VERSION "created by canmatrix"

NS_ :

BS_:

BU_: User ADM_PC_LL25 ADM_PC_BC25 ADM_PC_BP25 ADM_PC_BI25

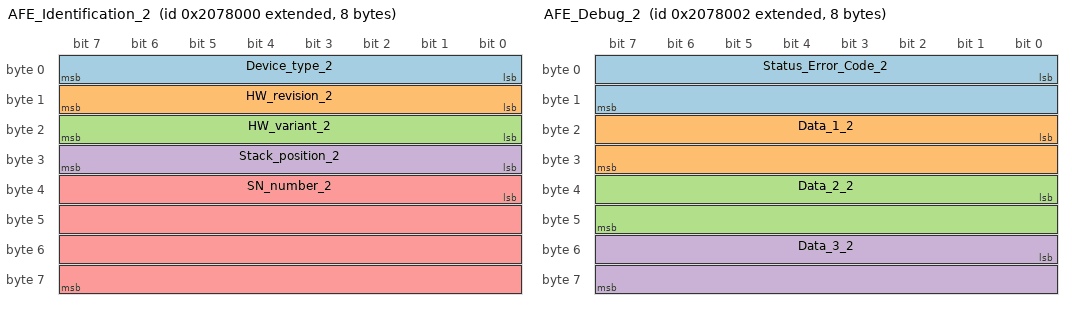
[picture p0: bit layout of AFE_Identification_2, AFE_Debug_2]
BO_ 2181529600 AFE_Identification_2: 8 ADM_PC_BP25
 SG_ Device_type_2 : 0|8@1+ (1,0) [0|255] "" Vector__XXX
 SG_ HW_revision_2 : 8|8@1+ (1,0) [0|255] "" Vector__XXX
 SG_ HW_variant_2 : 16|8@1+ (1,0) [0|255] "" Vector__XXX
 SG_ Stack_position_2 : 24|8@1+ (1,0) [0|255] "" Vector__XXX
 SG_ SN_number_2 : 32|32@1+ (1,0) [0|4294967295] "" Vector__XXX

BO_ 2181529601 AFE_FwInfo_2: 8 ADM_PC_BP25
 SG_ FW_info_mux_2 M : 56|8@1+ (1,0) [0|255] "" Vector__XXX
 SG_ FW_revision_0_2 m0 : 0|8@1+ (1,0) [0|255] "" Vector__XXX
 SG_ FW_revision_1_2 m0 : 8|8@1+ (1,0) [0|255] "" Vector__XXX
 SG_ FW_revision_2_2 m0 : 16|8@1+ (1,0) [0|255] "" Vector__XXX
 SG_ FW_revision_3_2 m0 : 24|8@1+ (1,0) [0|255] "" Vector__XXX
 SG_ FW_revision_4_2 m0 : 32|8@1+ (1,0) [0|255] "" Vector__XXX
 SG_ FW_revision_5_2 m0 : 40|8@1+ (1,0) [0|255] "" Vector__XXX
 SG_ FW_revision_6_2 m0 : 48|8@1+ (1,0) [0|255] "" Vector__XXX
 SG_ FW_revision_7_2 m1 : 0|8@1+ (1,0) [0|255] "" Vector__XXX
 SG_ FW_revision_8_2 m1 : 8|8@1+ (1,0) [0|255] "" Vector__XXX
 SG_ FW_revision_9_2 m1 : 16|8@1+ (1,0) [0|255] "" Vector__XXX
 SG_ FW_revision_10_2 m1 : 24|8@1+ (1,0) [0|255] "" Vector__XXX
 SG_ FW_revision_11_2 m1 : 32|8@1+ (1,0) [0|255] "" Vector__XXX
 SG_ FW_revision_12_2 m1 : 40|8@1+ (1,0) [0|255] "" Vector__XXX
 SG_ FW_revision_13_2 m1 : 48|8@1+ (1,0) [0|255] "" Vector__XXX
 SG_ FW_datecode_0_2 m2 : 0|8@1+ (1,0) [0|255] "" Vector__XXX
 SG_ FW_datecode_1_2 m2 : 8|8@1+ (1,0) [0|255] "" Vector__XXX
 SG_ FW_datecode_2_2 m2 : 16|8@1+ (1,0) [0|255] "" Vector__XXX
 SG_ FW_datecode_3_2 m2 : 24|8@1+ (1,0) [0|255] "" Vector__XXX
 SG_ FW_datecode_4_2 m2 : 32|8@1+ (1,0) [0|255] "" Vector__XXX
 SG_ FW_datecode_5_2 m2 : 40|8@1+ (1,0) [0|255] "" Vector__XXX
 SG_ FW_datecode_6_2 m2 : 48|8@1+ (1,0) [0|255] "" Vector__XXX
 SG_ FW_datecode_7_2 m3 : 0|8@1+ (1,0) [0|255] "" Vector__XXX
 SG_ FW_datecode_8_2 m3 : 8|8@1+ (1,0) [0|255] "" Vector__XXX
 SG_ FW_datecode_9_2 m3 : 16|8@1+ (1,0) [0|255] "" Vector__XXX
 SG_ FW_datecode_10_2 m3 : 24|8@1+ (1,0) [0|255] "" Vector__XXX
 SG_ FW_datecode_11_2 m3 : 32|8@1+ (1,0) [0|255] "" Vector__XXX
 SG_ FW_datecode_12_2 m3 : 40|8@1+ (1,0) [0|255] "" Vector__XXX
 SG_ FW_datecode_13_2 m3 : 48|8@1+ (1,0) [0|255] "" Vector__XXX

BO_ 2181529613 _AFE_Boot_FwInfo_2: 8 ADM_PC_BP25
 SG_ Boot_FW_info_mux_2 M : 56|8@1+ (1,0) [0|255] "" Vector__XXX
 SG_ FW_revision_0_2 m0 : 0|8@1+ (1,0) [0|255] "" Vector__XXX
 SG_ FW_revision_1_2 m0 : 8|8@1+ (1,0) [0|255] "" Vector__XXX
 SG_ FW_revision_2_2 m0 : 16|8@1+ (1,0) [0|255] "" Vector__XXX
 SG_ FW_revision_3_2 m0 : 24|8@1+ (1,0) [0|255] "" Vector__XXX
 SG_ FW_revision_4_2 m0 : 32|8@1+ (1,0) [0|255] "" Vector__XXX
 SG_ FW_revision_5_2 m0 : 40|8@1+ (1,0) [0|255] "" Vector__XXX
 SG_ FW_revision_6_2 m0 : 48|8@1+ (1,0) [0|255] "" Vector__XXX
 SG_ FW_revision_7_2 m1 : 0|8@1+ (1,0) [0|255] "" Vector__XXX
 SG_ FW_revision_8_2 m1 : 8|8@1+ (1,0) [0|255] "" Vector__XXX
 SG_ FW_revision_9_2 m1 : 16|8@1+ (1,0) [0|255] "" Vector__XXX
 SG_ FW_revision_10_2 m1 : 24|8@1+ (1,0) [0|255] "" Vector__XXX
 SG_ FW_revision_11_2 m1 : 32|8@1+ (1,0) [0|255] "" Vector__XXX
 SG_ FW_revision_12_2 m1 : 40|8@1+ (1,0) [0|255] "" Vector__XXX
 SG_ FW_revision_13_2 m1 : 48|8@1+ (1,0) [0|255] "" Vector__XXX
 SG_ FW_datecode_0_2 m2 : 0|8@1+ (1,0) [0|255] "" Vector__XXX
 SG_ FW_datecode_1_2 m2 : 8|8@1+ (1,0) [0|255] "" Vector__XXX
 SG_ FW_datecode_2_2 m2 : 16|8@1+ (1,0) [0|255] "" Vector__XXX
 SG_ FW_datecode_3_2 m2 : 24|8@1+ (1,0) [0|255] "" Vector__XXX
 SG_ FW_datecode_4_2 m2 : 32|8@1+ (1,0) [0|255] "" Vector__XXX
 SG_ FW_datecode_5_2 m2 : 40|8@1+ (1,0) [0|255] "" Vector__XXX
 SG_ FW_datecode_6_2 m2 : 48|8@1+ (1,0) [0|255] "" Vector__XXX
 SG_ FW_datecode_7_2 m3 : 0|8@1+ (1,0) [0|255] "" Vector__XXX
 SG_ FW_datecode_8_2 m3 : 8|8@1+ (1,0) [0|255] "" Vector__XXX
 SG_ FW_datecode_9_2 m3 : 16|8@1+ (1,0) [0|255] "" Vector__XXX
 SG_ FW_datecode_10_2 m3 : 24|8@1+ (1,0) [0|255] "" Vector__XXX
 SG_ FW_datecode_11_2 m3 : 32|8@1+ (1,0) [0|255] "" Vector__XXX
 SG_ FW_datecode_12_2 m3 : 40|8@1+ (1,0) [0|255] "" Vector__XXX
 SG_ FW_datecode_13_2 m3 : 48|8@1+ (1,0) [0|255] "" Vector__XXX

BO_ 2181529602 AFE_Debug_2: 8 ADM_PC_BP25
 SG_ Status_Error_Code_2 : 0|16@1+ (1,0) [0|65535] "" Vector__XXX
 SG_ Data_1_2 : 16|16@1+ (1,0) [0|65535] "" Vector__XXX
 SG_ Data_2_2 : 32|16@1+ (1,0) [0|65535] "" Vector__XXX
 SG_ Data_3_2 : 48|16@1+ (1,0) [0|65535] "" Vector__XXX

BO_ 2181529607 AFE_Status_2: 8 ADM_PC_BP25
 SG_ Running_2 : 0|1@1+ (1,0) [0|1] "" Vector__XXX
 SG_ PWM_2 : 1|1@1+ (1,0) [0|1] "" Vector__XXX
 SG_ Current_dc_loop_mode_2 : 2|1@1+ (1,0) [0|1] "" Vector__XXX
 SG_ Current_ac_loop_mode_2 : 3|1@1+ (1,0) [0|1] "" Vector__XXX
 SG_ Buck_2 : 5|1@1+ (1,0) [0|1] "" Vector__XXX
 SG_ Boost_2 : 6|1@1+ (1,0) [0|1] "" Vector__XXX
 SG_ Precharge_dc_buck_mode_2 : 7|1@1+ (1,0) [0|1] "" Vector__XXX
 SG_ Precharge_dc_boost_mode_2 : 8|1@1+ (1,0) [0|1] "" Vector__XXX
 SG_ Rectifier_3ph_2 : 9|1@1+ (1,0) [0|1] "" Vector__XXX
 SG_ Stack_mode_2 : 10|1@1+ (1,0) [0|1] "" Vector__XXX
 SG_ Master_2 : 11|1@1+ (1,0) [0|1] "" Vector__XXX
 SG_ Slave_2 : 12|1@1+ (1,0) [0|1] "" Vector__XXX
 SG_ Inverter_1ph_2 : 13|1@1+ (1,0) [0|1] "" Vector__XXX
 SG_ Boost_Neutral_2 : 14|1@1+ (1,0) [0|1] "" Vector__XXX
 SG_ Rectifier_1ph_2 : 15|1@1+ (1,0) [0|1] "" Vector__XXX
 SG_ Inverter_3ph_2 : 16|1@1+ (1,0) [0|1] "" Vector__XXX
 SG_ Ready_2 : 17|1@1+ (1,0) [0|1] "" Vector__XXX
 SG_ Inverter_1ph_Sync_2 : 18|1@1+ (1,0) [0|1] "" Vector__XXX
 SG_ Neutral_2 : 19|1@1+ (1,0) [0|1] "" Vector__XXX
 SG_ Rectifier_1ph_Buck_2 : 20|1@1+ (1,0) [0|1] "" Vector__XXX
 SG_ Inverter_1ph_Boost_2 : 21|1@1+ (1,0) [0|1] "" Vector__XXX
 SG_ Rectifier_distributed_2 : 22|1@1+ (1,0) [0|1] "" Vector__XXX
 SG_ MPPT_buck_2 : 23|1@1+ (1,0) [0|1] "" Vector__XXX
 SG_ MPPT_boost_2 : 24|1@1+ (1,0) [0|1] "" Vector__XXX
 SG_ Buck_2p_float_2 : 25|1@1+ (1,0) [0|1] "" Vector__XXX
 SG_ Inverter_1ph_Distributed_2 : 26|1@1+ (1,0) [0|1] "" Vector__XXX

BO_ 2181529606 AFE_Faults_2: 3 ADM_PC_BP25
 SG_ Protection_trip_internal_2 : 0|1@1+ (1,0) [0|1] "" Vector__XXX
 SG_ Protection_trip_external_2 : 1|1@1+ (1,0) [0|1] "" Vector__XXX
 SG_ Phase_U_overcurrent_2 : 2|1@1+ (1,0) [0|1] "" Vector__XXX
 SG_ Phase_U_overvoltage_2 : 3|1@1+ (1,0) [0|1] "" Vector__XXX
 SG_ Phase_U_undervoltage_2 : 4|1@1+ (1,0) [0|1] "" Vector__XXX
 SG_ Phase_V_overvoltage_2 : 5|1@1+ (1,0) [0|1] "" Vector__XXX
 SG_ Phase_V_undervoltage_2 : 6|1@1+ (1,0) [0|1] "" Vector__XXX
 SG_ Phase_V_overcurrent_2 : 7|1@1+ (1,0) [0|1] "" Vector__XXX
 SG_ Phase_W_overvoltage_2 : 8|1@1+ (1,0) [0|1] "" Vector__XXX
 SG_ Phase_W_undervoltage_2 : 9|1@1+ (1,0) [0|1] "" Vector__XXX
 SG_ Phase_W_overcurrent_2 : 10|1@1+ (1,0) [0|1] "" Vector__XXX
 SG_ DC_undervoltage_2 : 11|1@1+ (1,0) [0|1] "" Vector__XXX
 SG_ DC_overvoltage_2 : 12|1@1+ (1,0) [0|1] "" Vector__XXX
 SG_ MOSFET_overtemperature_2 : 13|1@1+ (1,0) [0|1] "" Vector__XXX
 SG_ Inductor_overtemperature_2 : 14|1@1+ (1,0) [0|1] "" Vector__XXX
 SG_ Keep_Alive_not_served_2 : 15|1@1+ (1,0) [0|1] "" Vector__XXX
 SG_ PLL_not_locked_2 : 16|1@1+ (1,0) [0|1] "" Vector__XXX
 SG_ NFO_2 : 20|1@1+ (1,0) [0|1] "" Vector__XXX
 SG_ Measurement_system_failure_2 : 21|1@1+ (1,0) [0|1] "" Vector__XXX
 SG_ EEPROM_failure_2 : 22|1@1+ (1,0) [0|1] "" Vector__XXX
 SG_ System_2 : 23|1@1+ (1,0) [0|1] "" Vector__XXX

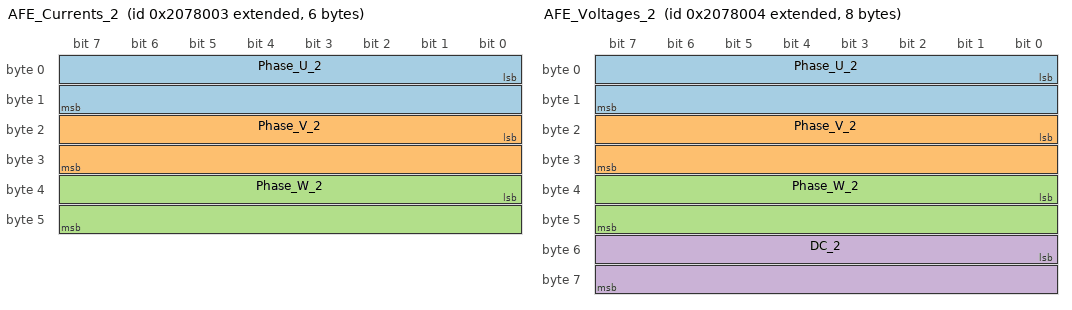
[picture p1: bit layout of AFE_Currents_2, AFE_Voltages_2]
BO_ 2181529603 AFE_Currents_2: 6 ADM_PC_BP25
 SG_ Phase_U_2 : 0|16@1- (0.01,0) [-327.68|327.67] "A" Vector__XXX
 SG_ Phase_V_2 : 16|16@1- (0.01,0) [-327.68|327.67] "A" Vector__XXX
 SG_ Phase_W_2 : 32|16@1- (0.01,0) [-327.68|327.67] "A" Vector__XXX

BO_ 2181529616 AFE_DC_Bus_current_2: 2 ADM_PC_BP25
 SG_ Bus_current_2 : 0|16@1- (0.01,0) [-327.68|327.67] "A" Vector__XXX

BO_ 2181529614 _AFE_Broadcast_2: 8 ADM_PC_BP25
 SG_ Diagnostics_Index_2 M : 56|8@1+ (1,0) [0|255] "" Vector__XXX
 SG_ Phase_U_2 m1 : 8|16@1- (0.01,0) [-327.68|327.67] "A" ADM_PC_BP25
 SG_ Phase_V_2 m1 : 24|16@1- (0.01,0) [-327.68|327.67] "A" ADM_PC_BP25
 SG_ Phase_W_2 m1 : 40|16@1- (0.01,0) [-327.68|327.67] "A" ADM_PC_BP25
 SG_ Stack_position_2 : 0|5@1+ (1,0) [0|31] "" ADM_PC_BP25
 SG_ Group_ID_2 : 5|3@1+ (1,0) [0|7] "" ADM_PC_BP25

BO_ 2181529604 AFE_Voltages_2: 8 ADM_PC_BP25
 SG_ Phase_U_2 : 0|16@1- (0.1,0) [-3276.8|3276.7] "V" Vector__XXX
 SG_ Phase_V_2 : 16|16@1- (0.1,0) [-3276.8|3276.7] "V" Vector__XXX
 SG_ Phase_W_2 : 32|16@1- (0.1,0) [-3276.8|3276.7] "V" Vector__XXX
 SG_ DC_2 : 48|16@1- (0.1,0) [-3276.8|3276.7] "V" Vector__XXX

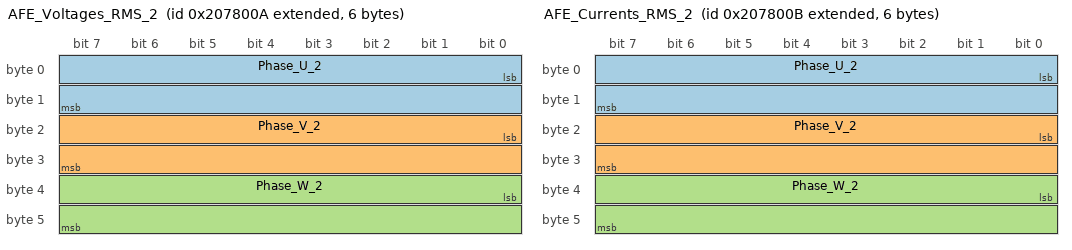
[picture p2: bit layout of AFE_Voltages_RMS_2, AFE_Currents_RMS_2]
BO_ 2181529610 AFE_Voltages_RMS_2: 6 ADM_PC_BP25
 SG_ Phase_U_2 : 0|16@1+ (0.1,0) [0|6553.5] "V" Vector__XXX
 SG_ Phase_V_2 : 16|16@1+ (0.1,0) [0|6553.5] "V" Vector__XXX
 SG_ Phase_W_2 : 32|16@1+ (0.1,0) [0|6553.5] "V" Vector__XXX

BO_ 2181529611 AFE_Currents_RMS_2: 6 ADM_PC_BP25
 SG_ Phase_U_2 : 0|16@1+ (0.01,0) [0.00|655.35] "A" Vector__XXX
 SG_ Phase_V_2 : 16|16@1+ (0.01,0) [0.00|655.35] "A" Vector__XXX
 SG_ Phase_W_2 : 32|16@1+ (0.01,0) [0.00|655.35] "A" Vector__XXX

BO_ 2181529612 AFE_Mains_2: 4 ADM_PC_BP25
 SG_ Frequency_2 : 0|16@1+ (0.01,0) [0.00|655.35] "Hz" Vector__XXX
 SG_ Phase_2 : 16|16@1- (0.1,0) [-3276.8|3276.7] "Deg." Vector__XXX

BO_ 2181529605 AFE_Temperatures_2: 4 ADM_PC_BP25
 SG_ Temp_Bridge_2 : 0|16@1- (0.01,0) [-327.68|327.67] "°C" Vector__XXX
 SG_ Temp_Inductors_2 : 16|16@1- (0.01,0) [-327.68|327.67] "°C" Vector__XXX

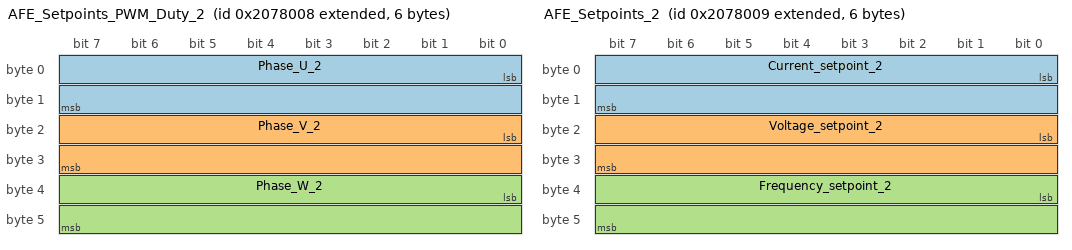
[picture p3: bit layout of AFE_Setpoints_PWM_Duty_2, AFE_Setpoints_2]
BO_ 2181529608 AFE_Setpoints_PWM_Duty_2: 6 ADM_PC_BP25
 SG_ Phase_U_2 : 0|16@1+ (0.001525902,0) [0E-009|99.999987570] "%" Vector__XXX
 SG_ Phase_V_2 : 16|16@1+ (0.001525902,0) [0E-009|99.999987570] "%" Vector__XXX
 SG_ Phase_W_2 : 32|16@1+ (0.001525902,0) [0E-009|99.999987570] "%" Vector__XXX

BO_ 2181529609 AFE_Setpoints_2: 6 ADM_PC_BP25
 SG_ Current_setpoint_2 : 0|16@1- (0.01,0) [-327.68|327.67] "A" Vector__XXX
 SG_ Voltage_setpoint_2 : 16|16@1+ (0.1,0) [0|6553.5] "V" Vector__XXX
 SG_ Frequency_setpoint_2 : 32|16@1+ (0.01,0) [0.00|655.35] "Hz" Vector__XXX

BO_ 2181496928 AFE_Keep_Alive_2: 1 User
 SG_ Keep_Alive_Enable_2 : 0|1@1+ (1,0) [0|1] "" ADM_PC_BP25

BO_ 2181496896 AFE_Mode_Control_2: 8 User
 SG_ Converter_ON_2 : 0|1@1+ (1,0) [0|1] "" ADM_PC_BP25
 SG_ PWM_ON_2 : 1|1@1+ (1,0) [0|1] "" ADM_PC_BP25
 SG_ DC_Current_feedback_ON_2 : 2|1@1+ (1,0) [0|1] "" ADM_PC_BP25
 SG_ AC_Current_feedback_ON_2 : 3|1@1+ (1,0) [0|1] "" ADM_PC_BP25
 SG_ Buck_ON_2 : 5|1@1+ (1,0) [0|1] "" ADM_PC_BP25
 SG_ Boost_ON_2 : 6|1@1+ (1,0) [0|1] "" ADM_PC_BP25
 SG_ Rectifier_3ph_ON_2 : 9|1@1+ (1,0) [0|1] "" ADM_PC_BP25
 SG_ Inverter_1ph_ON_2 : 10|1@1+ (1,0) [0|1] "" ADM_PC_BP25
 SG_ Rectifier_1ph_ON_2 : 11|1@1+ (1,0) [0|1] "" ADM_PC_BP25
 SG_ Boost_Neutral_ON_2 : 12|1@1+ (1,0) [0|1] "" ADM_PC_BP25
 SG_ Inverter_3ph_ON_2 : 13|1@1+ (1,0) [0|1] "" ADM_PC_BP25
 SG_ Inverter_1ph_Sync_ON_2 : 14|1@1+ (1,0) [0|1] "" ADM_PC_BP25
 SG_ Neutral_ON_2 : 15|1@1+ (1,0) [0|1] "" ADM_PC_BP25
 SG_ Rectifier_1ph_Buck_ON_2 : 16|1@1+ (1,0) [0|1] "" ADM_PC_BP25
 SG_ Inverter_1ph_Boost_ON_2 : 17|1@1+ (1,0) [0|1] "" ADM_PC_BP25
 SG_ Rectifier_Distributed_ON_2 : 18|1@1+ (1,0) [0|1] "" ADM_PC_BP25
 SG_ MPPT_buck_ON_2 : 19|1@1+ (1,0) [0|1] "" ADM_PC_BP25
 SG_ MPPT_boost_ON_2 : 20|1@1+ (1,0) [0|1] "" ADM_PC_BP25
 SG_ Buck_2p_float_ON_2 : 21|1@1+ (1,0) [0|1] "" ADM_PC_BP25
 SG_ Inverter_1ph_Distributed_ON_2 : 22|1@1+ (1,0) [0|1] "" ADM_PC_BP25

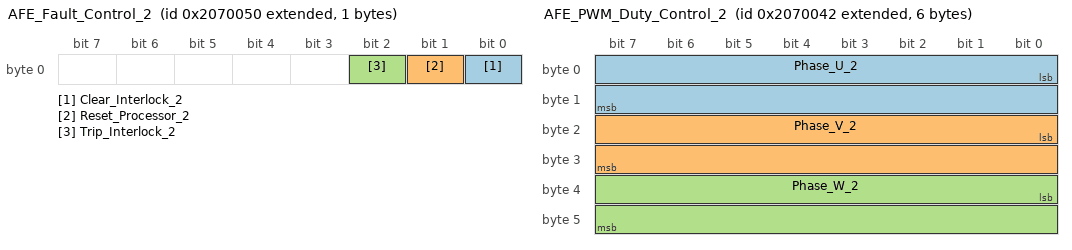
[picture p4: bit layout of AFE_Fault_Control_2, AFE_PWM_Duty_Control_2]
BO_ 2181496912 AFE_Fault_Control_2: 1 User
 SG_ Clear_Interlock_2 : 0|1@1+ (1,0) [0|1] "" ADM_PC_BP25
 SG_ Reset_Processor_2 : 1|1@1+ (1,0) [0|1] "" ADM_PC_BP25
 SG_ Trip_Interlock_2 : 2|1@1+ (1,0) [0|1] "" ADM_PC_BP25

BO_ 2181496897 AFE_Reactive_Current_Setpoint_Co: 2 User
 SG_ Reactive_current_setpoint_2 : 0|16@1- (0.01,0) [-150|150] "A" ADM_PC_BP25

BO_ 2181496898 AFE_PWM_Duty_Control_2: 6 User
 SG_ Phase_U_2 : 0|16@1+ (0.001525902,0) [0E-009|99.999987570] "%" ADM_PC_BP25
 SG_ Phase_V_2 : 16|16@1+ (0.001525902,0) [0E-009|99.999987570] "%" ADM_PC_BP25
 SG_ Phase_W_2 : 32|16@1+ (0.001525902,0) [0E-009|99.999987570] "%" ADM_PC_BP25

BO_ 2181496899 AFE_Current_Setpoint_Control_2: 2 User
 SG_ Current_setpoint_2 : 0|16@1- (0.01,0) [-150|150] "A" ADM_PC_BP25

BO_ 2181496900 AFE_Voltage_Setpoint_Control_2: 2 User
 SG_ Voltage_setpoint_2 : 0|16@1+ (0.1,0) [0|1500] "V" ADM_PC_BP25

BO_ 2181496904 AFE_Frequency_Setpoint_Control_2: 2 User
 SG_ Frequency_setpoint_2 : 0|16@1+ (0.01,0) [40|70] "Hz" ADM_PC_BP25

BO_ 2181496905 AFE_Phase_Setpoint_Control_2: 2 User
 SG_ Phase_setpoint_2 : 0|16@1+ (1,0) [0|360] "deg" ADM_PC_BP25

BO_ 2181496944 AFE_Rectifier_Setpoint_Control_2: 8 User
 SG_ Voltage_setpoint_2_2 : 0|16@1+ (0.1,0) [0|1500] "V" ADM_PC_BP25
 SG_ Current_setpoint_2_2 : 16|16@1- (0.01,0) [-150|150] "A" ADM_PC_BP25

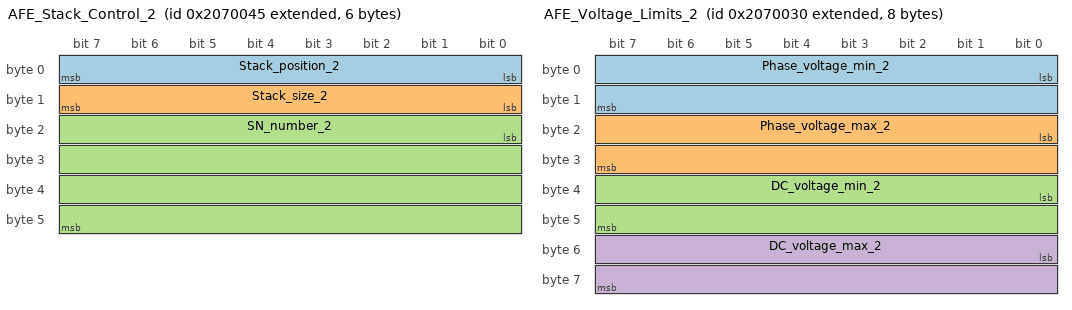
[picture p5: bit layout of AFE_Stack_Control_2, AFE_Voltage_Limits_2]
BO_ 2181496901 AFE_Stack_Control_2: 6 User
 SG_ Stack_position_2 : 0|8@1+ (1,0) [0|255] "" ADM_PC_BP25
 SG_ Stack_size_2 : 8|8@1+ (1,0) [0|255] "" ADM_PC_BP25
 SG_ SN_number_2 : 16|32@1+ (1,0) [0|4294967295] "" ADM_PC_BP25

BO_ 2181496880 AFE_Voltage_Limits_2: 8 User
 SG_ Phase_voltage_min_2 : 0|16@1- (0.1,0) [0|3276.7] "V" ADM_PC_BP25
 SG_ Phase_voltage_max_2 : 16|16@1- (0.1,0) [-3276.8|850] "V" ADM_PC_BP25
 SG_ DC_voltage_min_2 : 32|16@1- (0.1,0) [0|3276.7] "V" ADM_PC_BP25
 SG_ DC_voltage_max_2 : 48|16@1- (0.1,0) [-3276.8|850] "V" ADM_PC_BP25

BO_ 2181496881 AFE_Current_Limits_2: 4 User
 SG_ Phase_current_min_2 : 0|16@1- (0.01,0) [-60|60] "A" ADM_PC_BP25
 SG_ Phase_current_max_2 : 16|16@1- (0.01,0) [-60|60] "A" ADM_PC_BP25

BO_ 2181496908 AFE_Group_Control_2: 1 User
 SG_ Group_ID_2 : 0|8@1+ (1,0) [0|255] "" ADM_PC_BP25

BO_ 2181529615 AFE_Group_Info_2: 1 ADM_PC_BP25
 SG_ Group_ID_2 : 0|8@1+ (1,0) [0|255] "" Vector__XXX

BO_ 2181496929 AFE_System_Flags_Control_2: 8 User
 SG_ Factory_mode_2 : 0|1@1+ (1,0) [0|1] "" ADM_PC_BP25
 SG_ Silent_CAN_mode_2 : 1|1@1+ (1,0) [0|1] "" ADM_PC_BP25

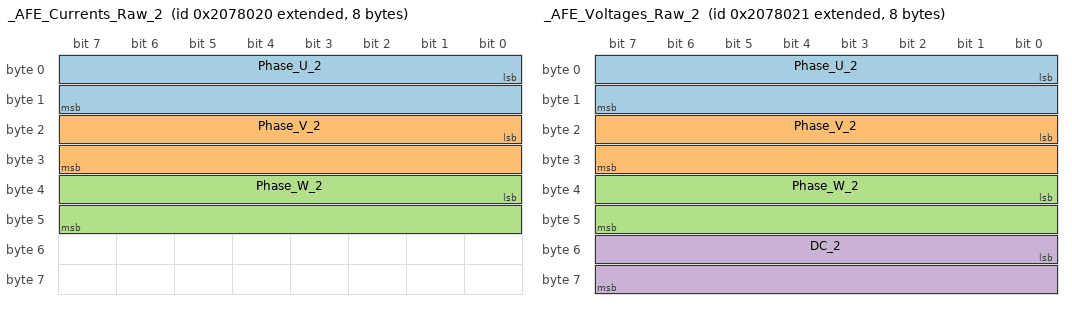
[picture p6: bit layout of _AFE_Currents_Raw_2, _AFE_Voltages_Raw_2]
BO_ 2181529632 _AFE_Currents_Raw_2: 8 ADM_PC_BP25
 SG_ Phase_U_2 : 0|16@1- (1,0) [-32768|32767] "" Vector__XXX
 SG_ Phase_V_2 : 16|16@1- (1,0) [-32768|32767] "" Vector__XXX
 SG_ Phase_W_2 : 32|16@1- (1,0) [-32768|32767] "" Vector__XXX

BO_ 2181529633 _AFE_Voltages_Raw_2: 8 ADM_PC_BP25
 SG_ Phase_U_2 : 0|16@1- (1,0) [-32768|32767] "" Vector__XXX
 SG_ Phase_V_2 : 16|16@1- (1,0) [-32768|32767] "" Vector__XXX
 SG_ Phase_W_2 : 32|16@1- (1,0) [-32768|32767] "" Vector__XXX
 SG_ DC_2 : 48|16@1- (1,0) [-32768|32767] "" Vector__XXX

BO_ 2181496906 _AFE_ADC_Calibration_Mode_2: 1 User
 SG_ Calibration_Index_2 M : 2|5@1+ (1,0) [0|31] "" Vector__XXX
 SG_ Current_U_2 m1 : 0|2@1+ (1,0) [0|3] "" ADM_PC_BP25
 SG_ Current_V_2 m2 : 0|2@1+ (1,0) [0|3] "" ADM_PC_BP25
 SG_ Current_W_2 m3 : 0|2@1+ (1,0) [0|3] "" ADM_PC_BP25
 SG_ Voltage_U_2 m4 : 0|2@1+ (1,0) [0|3] "" ADM_PC_BP25
 SG_ Voltage_V_2 m5 : 0|2@1+ (1,0) [0|3] "" ADM_PC_BP25
 SG_ Voltage_W_2 m6 : 0|2@1+ (1,0) [0|3] "" ADM_PC_BP25
 SG_ Voltage_DC_2 m7 : 0|2@1+ (1,0) [0|3] "" ADM_PC_BP25
 SG_ start_2 : 7|1@1+ (1,0) [0|1] "" ADM_PC_BP25

BO_ 2181496907 _AFE_ADC_Calibration_Setpoint_2: 3 User
 SG_ Calibration_Index_2 M : 16|5@1+ (1,0) [0|31] "" Vector__XXX
 SG_ Current_U_2 m1 : 0|16@1- (0.01,0) [-100|100] "A" ADM_PC_BP25
 SG_ Current_V_2 m2 : 0|16@1- (0.01,0) [-100|100] "A" ADM_PC_BP25
 SG_ Current_W_2 m3 : 0|16@1- (0.01,0) [-100|100] "A" ADM_PC_BP25
 SG_ Voltage_U_2 m4 : 0|16@1+ (0.1,0) [0|1500] "V" ADM_PC_BP25
 SG_ Voltage_V_2 m5 : 0|16@1+ (0.1,0) [0|1500] "V" ADM_PC_BP25
 SG_ Voltage_W_2 m6 : 0|16@1+ (0.1,0) [0|1500] "V" ADM_PC_BP25
 SG_ Voltage_DC_2 m7 : 0|16@1+ (0.1,0) [0|1500] "V" ADM_PC_BP25
 SG_ point_2 : 21|3@1+ (1,0) [0|7] "" ADM_PC_BP25

BO_ 2181496902 _AFE_Calibration_Offset_Update_2: 6 User
 SG_ Calibration_Index_2 M : 16|16@1+ (1,0) [0|65535] "" Vector__XXX
 SG_ Current_U_2 m0 : 0|16@1- (1,0) [-32768|32767] "ADC Counts" ADM_PC_BP25
 SG_ Current_V_2 m1 : 0|16@1- (1,0) [-32768|32767] "ADC Counts" ADM_PC_BP25
 SG_ Current_W_2 m2 : 0|16@1- (1,0) [-32768|32767] "ADC Counts" ADM_PC_BP25
 SG_ Voltage_U_2 m3 : 0|16@1- (1,0) [-32768|32767] "ADC Counts" ADM_PC_BP25
 SG_ Voltage_V_2 m4 : 0|16@1- (1,0) [-32768|32767] "ADC Counts" ADM_PC_BP25
 SG_ Voltage_W_2 m5 : 0|16@1- (1,0) [-32768|32767] "ADC Counts" ADM_PC_BP25
 SG_ Voltage_DC_2 m6 : 0|16@1- (1,0) [-32768|32767] "ADC Counts" ADM_PC_BP25
 SG_ CRC_2 : 32|16@1+ (1,0) [0|65535] "-" ADM_PC_BP25

BO_ 2181496903 _AFE_Calibration_Scale_Update_2: 6 User
 SG_ Calibration_Index_2 M : 16|16@1+ (1,0) [0|65535] "" Vector__XXX
 SG_ Current_U_2 m0 : 0|16@1- (0.0000152587890625,0) [-0.5000000000000000|0.4999847412109375] "scale = 1.0 + value" ADM_PC_BP25
 SG_ Current_V_2 m1 : 0|16@1- (0.0000152587890625,0) [-0.5000000000000000|0.4999847412109375] "scale = 1.0 + value" ADM_PC_BP25
 SG_ Current_W_2 m2 : 0|16@1- (0.0000152587890625,0) [-0.5000000000000000|0.4999847412109375] "scale = 1.0 + value" ADM_PC_BP25
 SG_ Voltage_U_2 m3 : 0|16@1- (0.0000152587890625,0) [-0.5000000000000000|0.4999847412109375] "scale = 1.0 + value" ADM_PC_BP25
 SG_ Voltage_V_2 m4 : 0|16@1- (0.0000152587890625,0) [-0.5000000000000000|0.4999847412109375] "scale = 1.0 + value" ADM_PC_BP25
 SG_ Voltage_W_2 m5 : 0|16@1- (0.0000152587890625,0) [-0.5000000000000000|0.4999847412109375] "scale = 1.0 + value" ADM_PC_BP25
 SG_ Voltage_DC_2 m6 : 0|16@1- (0.0000152587890625,0) [-0.5000000000000000|0.4999847412109375] "scale = 1.0 + value" ADM_PC_BP25
 SG_ CRC_2 : 32|16@1+ (1,0) [0|65535] "-" ADM_PC_BP25

BO_ 2181529681 _AFE_Calibration_Adc_Scale_2: 6 ADM_PC_BP25
 SG_ Adc_Index_2 M : 32|16@1+ (1,0) [0|65535] "" Vector__XXX
 SG_ Current_U_2 m0 : 0|32@1+ (1,0) [0|4294967295] "1 / adc_bins" User
 SG_ Current_V_2 m1 : 0|32@1+ (1,0) [0|4294967295] "1 / adc_bins" User
 SG_ Current_W_2 m2 : 0|32@1+ (1,0) [0|4294967295] "1 / adc_bins" User
 SG_ Voltage_U_2 m3 : 0|32@1+ (1,0) [0|4294967295] "1 / adc_bins" User
 SG_ Voltage_V_2 m4 : 0|32@1+ (1,0) [0|4294967295] "1 / adc_bins" User
 SG_ Voltage_W_2 m5 : 0|32@1+ (1,0) [0|4294967295] "1 / adc_bins" User
 SG_ Voltage_DC_2 m6 : 0|32@1+ (1,0) [0|4294967295] "1 / adc_bins" User

BO_ 2181529682 _AFE_Calibration_Adc_Fs_2: 6 ADM_PC_BP25
 SG_ Adc_Index_2 M : 32|16@1+ (1,0) [0|65535] "" Vector__XXX
 SG_ Current_U_2 m0 : 0|32@1+ (1,0) [0|4294967295] "Fullscale" User
 SG_ Current_V_2 m1 : 0|32@1+ (1,0) [0|4294967295] "Fullscale" User
 SG_ Current_W_2 m2 : 0|32@1+ (1,0) [0|4294967295] "Fullscale" User
 SG_ Voltage_U_2 m3 : 0|32@1+ (1,0) [0|4294967295] "Fullscale" User
 SG_ Voltage_V_2 m4 : 0|32@1+ (1,0) [0|4294967295] "Fullscale" User
 SG_ Voltage_W_2 m5 : 0|32@1+ (1,0) [0|4294967295] "Fullscale" User
 SG_ Voltage_DC_2 m6 : 0|32@1+ (1,0) [0|4294967295] "Fullscale" User

BO_ 2181529683 _AFE_Calibration_Adc_Offset_2: 4 ADM_PC_BP25
 SG_ Adc_Index_2 M : 16|16@1+ (1,0) [0|65535] "" Vector__XXX
 SG_ Current_U_2 m0 : 0|16@1- (1,0) [-32768|32767] "-" User
 SG_ Current_V_2 m1 : 0|16@1- (1,0) [-32768|32767] "-" User
 SG_ Current_W_2 m2 : 0|16@1- (1,0) [-32768|32767] "-" User
 SG_ Voltage_U_2 m3 : 0|16@1- (1,0) [-32768|32767] "-" User
 SG_ Voltage_V_2 m4 : 0|16@1- (1,0) [-32768|32767] "-" User
 SG_ Voltage_W_2 m5 : 0|16@1- (1,0) [-32768|32767] "-" User
 SG_ Voltage_DC_2 m6 : 0|16@1- (1,0) [-32768|32767] "-" User

BO_ 2181529684 _AFE_Calibration_Adc_Gain_2: 4 ADM_PC_BP25
 SG_ Adc_Index_2 M : 16|16@1+ (1,0) [0|65535] "" Vector__XXX
 SG_ Current_U_2 m0 : 0|16@1- (1,0) [-32768|32767] "-" User
 SG_ Current_V_2 m1 : 0|16@1- (1,0) [-32768|32767] "-" User
 SG_ Current_W_2 m2 : 0|16@1- (1,0) [-32768|32767] "-" User
 SG_ Voltage_U_2 m3 : 0|16@1- (1,0) [-32768|32767] "-" User
 SG_ Voltage_V_2 m4 : 0|16@1- (1,0) [-32768|32767] "-" User
 SG_ Voltage_W_2 m5 : 0|16@1- (1,0) [-32768|32767] "-" User
 SG_ Voltage_DC_2 m6 : 0|16@1- (1,0) [-32768|32767] "-" User

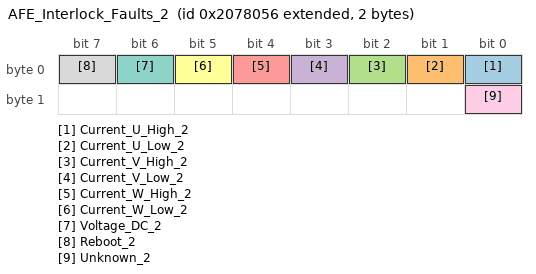
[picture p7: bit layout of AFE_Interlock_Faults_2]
BO_ 2181529686 AFE_Interlock_Faults_2: 2 ADM_PC_BP25
 SG_ Current_U_High_2 : 0|1@1+ (1,0) [0|1] "" Vector__XXX
 SG_ Current_U_Low_2 : 1|1@1+ (1,0) [0|1] "" Vector__XXX
 SG_ Current_V_High_2 : 2|1@1+ (1,0) [0|1] "" Vector__XXX
 SG_ Current_V_Low_2 : 3|1@1+ (1,0) [0|1] "" Vector__XXX
 SG_ Current_W_High_2 : 4|1@1+ (1,0) [0|1] "" Vector__XXX
 SG_ Current_W_Low_2 : 5|1@1+ (1,0) [0|1] "" Vector__XXX
 SG_ Voltage_DC_2 : 6|1@1+ (1,0) [0|1] "" Vector__XXX
 SG_ Reboot_2 : 7|1@1+ (1,0) [0|1] "" Vector__XXX
 SG_ Unknown_2 : 8|1@1+ (1,0) [0|1] "" Vector__XXX

BO_TX_BU_ 2181496896 : User,ADM_PC_LL25,ADM_PC_BC25,ADM_PC_BI25;
BO_TX_BU_ 2181496899 : User,ADM_PC_LL25,ADM_PC_BC25,ADM_PC_BI25;
BO_TX_BU_ 2181496900 : User,ADM_PC_LL25,ADM_PC_BC25,ADM_PC_BI25;
CM_ BO_ 2181529600  "Identification of the device";
CM_ BO_ 2181529601  "Git revision of the DSP firmware";
CM_ BO_ 2181529613  "Git revision of the bootloader firmware.";
CM_ BO_ 2181529602  "Values for debugging of HW/SW problems";
CM_ BO_ 2181529607  "Status bitfield";
CM_ BO_ 2181529606  "Fault bitfield";
CM_ BO_ 2181529603  "Current of phases U, V, W";
CM_ BO_ 2181529616  "Current of of the DC Bus";
CM_ BO_ 2181529614  "All AFEs will listen to this message";
CM_ BO_ 2181529611  "RMS Current of phases U, V, W";
CM_ BO_ 2181529612  "Three-Phase mains health (frequency, phase...)";
CM_ BO_ 2181529605  "Readouts of the module temperature sensors";
CM_ BO_ 2181529608  "Setpoints";
CM_ BO_ 2181529609  "Setpoints";
CM_ BO_ 2181496928  "Keep alive ping message. ";
CM_ BO_ 2181496896  "Operation Mode control: sets the converter operation mode";
CM_ BO_ 2181496912  "Fault Control: actions to clear faults and reset the system";
CM_ BO_ 2181496897  "Reactive power setpoint control.";
CM_ BO_ 2181496898  "PWM duty cycle control";
CM_ BO_ 2181496899  "Current setpoint control";
CM_ BO_ 2181496900  "Voltage setpoint control";
CM_ BO_ 2181496904  "Frequency setpoint control";
CM_ BO_ 2181496905  "Phase setpoint control";
CM_ BO_ 2181496944  "Additional voltage and current setpoints in single-phase rectifier and inverter control modes.";
CM_ BO_ 2181496901  "PFC stack control";
CM_ BO_ 2181496880  "Set the input and output voltage limits (minimum and maximum)";
CM_ BO_ 2181496881  "Set the output current limits (mminimum and maximum)";
CM_ BO_ 2181496908  "Set the Group ID of the device";
CM_ BO_ 2181529615  "Contains the Group ID of the device";
CM_ BO_ 2181496929  "Control the system flags";
CM_ BO_ 2181529632  "Current of phases A and B";
CM_ BO_ 2181529633  "Current of phases A and B";
CM_ BO_ 2181496906  "Automatic ADC calibration.";
CM_ BO_ 2181496907  "Setpoint for automatic ADC calibration.";
CM_ BO_ 2181496902  "Update of the calibration table for offsets.";
CM_ BO_ 2181496903  "Update of the calibration table for scales.";
CM_ BO_ 2181529681  "
                Adc scale (resolution) value of readouts.
            ";
CM_ BO_ 2181529682  "
                Adc fullscale value of readouts.
            ";
CM_ BO_ 2181529683  "
                Readout of ADC calibration data (offset) from EEPROM.
            ";
CM_ BO_ 2181529684  "
                Readout of ADC calibration data (gain) from EEPROM.
            ";
CM_ BO_ 2181529686  "Fault bitfield";

CM_ SG_ 2181529600 Device_type_2 "The device identification field, uniquely identifies the sender in the network";
CM_ SG_ 2181529600 HW_revision_2 "The hardware revision number";
CM_ SG_ 2181529600 HW_variant_2 "The DSP firmware revision number";
CM_ SG_ 2181529600 Stack_position_2 "Position of the module within the stack";
CM_ SG_ 2181529600 SN_number_2 "Unique module serial number";
CM_ SG_ 2181529601 FW_revision_0_2 "Character 0";
CM_ SG_ 2181529601 FW_revision_1_2 "Character 1";
CM_ SG_ 2181529601 FW_revision_2_2 "Character 2";
CM_ SG_ 2181529601 FW_revision_3_2 "Character 3";
CM_ SG_ 2181529601 FW_revision_4_2 "Character 3";
CM_ SG_ 2181529601 FW_revision_5_2 "Character 3";
CM_ SG_ 2181529601 FW_revision_6_2 "Character 3";
CM_ SG_ 2181529601 FW_revision_7_2 "Character 7";
CM_ SG_ 2181529601 FW_revision_8_2 "Character 8";
CM_ SG_ 2181529601 FW_revision_9_2 "Character 9";
CM_ SG_ 2181529601 FW_revision_10_2 "Character 10";
CM_ SG_ 2181529601 FW_revision_11_2 "Character 11";
CM_ SG_ 2181529601 FW_revision_12_2 "Character 12";
CM_ SG_ 2181529601 FW_revision_13_2 "Character 13";
CM_ SG_ 2181529601 FW_datecode_0_2 "Character 0";
CM_ SG_ 2181529601 FW_datecode_1_2 "Character 1";
CM_ SG_ 2181529601 FW_datecode_2_2 "Character 2";
CM_ SG_ 2181529601 FW_datecode_3_2 "Character 3";
CM_ SG_ 2181529601 FW_datecode_4_2 "Character 3";
CM_ SG_ 2181529601 FW_datecode_5_2 "Character 3";
CM_ SG_ 2181529601 FW_datecode_6_2 "Character 3";
CM_ SG_ 2181529601 FW_datecode_7_2 "Character 7";
CM_ SG_ 2181529601 FW_datecode_8_2 "Character 8";
CM_ SG_ 2181529601 FW_datecode_9_2 "Character 9";
CM_ SG_ 2181529601 FW_datecode_10_2 "Character 10";
CM_ SG_ 2181529601 FW_datecode_11_2 "Character 11";
CM_ SG_ 2181529601 FW_datecode_12_2 "Character 12";
CM_ SG_ 2181529601 FW_datecode_13_2 "Character 13";
CM_ SG_ 2181529613 FW_revision_0_2 "Character 0";
CM_ SG_ 2181529613 FW_revision_1_2 "Character 1";
CM_ SG_ 2181529613 FW_revision_2_2 "Character 2";
CM_ SG_ 2181529613 FW_revision_3_2 "Character 3";
CM_ SG_ 2181529613 FW_revision_4_2 "Character 3";
CM_ SG_ 2181529613 FW_revision_5_2 "Character 3";
CM_ SG_ 2181529613 FW_revision_6_2 "Character 3";
CM_ SG_ 2181529613 FW_revision_7_2 "Character 7";
CM_ SG_ 2181529613 FW_revision_8_2 "Character 8";
CM_ SG_ 2181529613 FW_revision_9_2 "Character 9";
CM_ SG_ 2181529613 FW_revision_10_2 "Character 10";
CM_ SG_ 2181529613 FW_revision_11_2 "Character 11";
CM_ SG_ 2181529613 FW_revision_12_2 "Character 12";
CM_ SG_ 2181529613 FW_revision_13_2 "Character 13";
CM_ SG_ 2181529613 FW_datecode_0_2 "Character 0";
CM_ SG_ 2181529613 FW_datecode_1_2 "Character 1";
CM_ SG_ 2181529613 FW_datecode_2_2 "Character 2";
CM_ SG_ 2181529613 FW_datecode_3_2 "Character 3";
CM_ SG_ 2181529613 FW_datecode_4_2 "Character 3";
CM_ SG_ 2181529613 FW_datecode_5_2 "Character 3";
CM_ SG_ 2181529613 FW_datecode_6_2 "Character 3";
CM_ SG_ 2181529613 FW_datecode_7_2 "Character 7";
CM_ SG_ 2181529613 FW_datecode_8_2 "Character 8";
CM_ SG_ 2181529613 FW_datecode_9_2 "Character 9";
CM_ SG_ 2181529613 FW_datecode_10_2 "Character 10";
CM_ SG_ 2181529613 FW_datecode_11_2 "Character 11";
CM_ SG_ 2181529613 FW_datecode_12_2 "Character 12";
CM_ SG_ 2181529613 FW_datecode_13_2 "Character 13";
CM_ SG_ 2181529602 Status_Error_Code_2 "Main status / error code as defined in errno/errno.h";
CM_ SG_ 2181529602 Data_1_2 "Additional information for the error/status";
CM_ SG_ 2181529602 Data_2_2 "Additional information for the error/status";
CM_ SG_ 2181529602 Data_3_2 "Additional information for the error/status";
CM_ SG_ 2181529607 Running_2 "Indicates if converter is running.";
CM_ SG_ 2181529607 PWM_2 "Indicates if converter is in PWM control mode.";
CM_ SG_ 2181529607 Current_dc_loop_mode_2 "Indicates if the current DC loop is enabled.";
CM_ SG_ 2181529607 Current_ac_loop_mode_2 "Indicates if the current AC loop is enabled.";
CM_ SG_ 2181529607 Buck_2 "Indicates if converter is in buck control mode.";
CM_ SG_ 2181529607 Boost_2 "Indicates if converter is in boost control mode.";
CM_ SG_ 2181529607 Precharge_dc_buck_mode_2 "Indicates if the precharge DC mode is enabled - buck direction.";
CM_ SG_ 2181529607 Precharge_dc_boost_mode_2 "Indicates if the precharge DC mode is enabled - boost direction.";
CM_ SG_ 2181529607 Rectifier_3ph_2 "Indicates if converter is in three-phase rectifier control mode.";
CM_ SG_ 2181529607 Stack_mode_2 "Indicates if converter is operating in stack mode.";
CM_ SG_ 2181529607 Master_2 "Indicates if converter is master in the stack.";
CM_ SG_ 2181529607 Slave_2 "Indicates if converter is slave in the stack.";
CM_ SG_ 2181529607 Inverter_1ph_2 "Indicates if converter is in single-phase inverter control mode.";
CM_ SG_ 2181529607 Boost_Neutral_2 "Indicates if converter is in boost control mode with neutral generation.";
CM_ SG_ 2181529607 Rectifier_1ph_2 "Indicates if converter is in single-phase rectifier control mode.";
CM_ SG_ 2181529607 Inverter_3ph_2 "Indicates if converter is in three-phase inverter control mode.";
CM_ SG_ 2181529607 Ready_2 "Indicates if converter is ready for operation.";
CM_ SG_ 2181529607 Inverter_1ph_Sync_2 "Single-phase inverter control mode with phase synchronization.";
CM_ SG_ 2181529607 Neutral_2 "Open-loop neutral generation.";
CM_ SG_ 2181529607 Rectifier_1ph_Buck_2 "Single-phase rectifier with buck on one leg.";
CM_ SG_ 2181529607 Inverter_1ph_Boost_2 "Single-phase inverter with boost on one leg.";
CM_ SG_ 2181529607 Rectifier_distributed_2 "Not available at the moment";
CM_ SG_ 2181529607 MPPT_buck_2 "Not available at the moment";
CM_ SG_ 2181529607 MPPT_boost_2 "Not available at the moment";
CM_ SG_ 2181529607 Buck_2p_float_2 "Buck in phases L1 and L2. Phase L3 is left floating (high impedance)";
CM_ SG_ 2181529607 Inverter_1ph_Distributed_2 "Single-phase inverter mode  distributed";
CM_ SG_ 2181529606 Protection_trip_internal_2 "This flagg is asserted if the interlock is open due to an internal fault condition (self-protection)";
CM_ SG_ 2181529606 Protection_trip_external_2 "This flag is asserted if the interlock is open due to an external condition received in the module.";
CM_ SG_ 2181529606 Phase_U_overcurrent_2 "Indicates an overcurrent event on Phase U. The overcurrent event is triggered when the measured phase current is over the programmed current limit.";
CM_ SG_ 2181529606 Phase_U_overvoltage_2 "Indicates an overvoltage event on Phase U. The overvoltage event is triggered when the measured phase voltage is over the programmed voltage limit.";
CM_ SG_ 2181529606 Phase_U_undervoltage_2 "Indicates an undervoltage event on Phase U. The overvoltage event is triggered when the measured phase voltage is over the programmed voltage limit.";
CM_ SG_ 2181529606 Phase_V_overvoltage_2 "Indicates an overvoltage event on Phase V. The overvoltage event is triggered when the measured phase voltage is over the programmed voltage limit.";
CM_ SG_ 2181529606 Phase_V_undervoltage_2 "Indicates an undervoltage event on Phase U. The overvoltage event is triggered when the measured phase voltage is over the programmed voltage limit.";
CM_ SG_ 2181529606 Phase_V_overcurrent_2 "Indicates an overcurrent event on Phase U. The overcurrent event is triggered when the measured phase current is over the programmed current limit.";
CM_ SG_ 2181529606 Phase_W_overvoltage_2 "Indicates an overvoltage event on Phase U. The overvoltage event is triggered when the measured phase voltage is over the programmed voltage limit.";
CM_ SG_ 2181529606 Phase_W_undervoltage_2 "Indicates an undervoltage event on Phase U. The overvoltage event is triggered when the measured phase voltage is over the programmed voltage limit.";
CM_ SG_ 2181529606 Phase_W_overcurrent_2 "Indicates an overcurrent event on Phase U. The overcurrent event is triggered when the measured phase current is over the programmed current limit.";
CM_ SG_ 2181529606 DC_undervoltage_2 "DC bus undervoltage condition. The undervoltage condition is asserted when the measured dc bus voltage is under the programmed voltage limit.";
CM_ SG_ 2181529606 DC_overvoltage_2 "DC bus overvoltage condition. The overvoltage condition is asserted when the measured dc bus voltage is over the programmed voltage limit.";
CM_ SG_ 2181529606 MOSFET_overtemperature_2 "This flag is asserted when the temperature of the MOSFET block is too high.";
CM_ SG_ 2181529606 Inductor_overtemperature_2 "This flag is asserted when the temperature of the inductor block is too high.";
CM_ SG_ 2181529606 Keep_Alive_not_served_2 "The Keep Alive feature is enabled but it was not served with the periodic message.";
CM_ SG_ 2181529606 PLL_not_locked_2 "Flag asserted when in rectifier modes, the PLL went out of lock condition";
CM_ SG_ 2181529606 Measurement_system_failure_2 "The voltages/currents measurement system is malfunctionning, and readouts are not guaranteed to be accurate.";
CM_ SG_ 2181529606 EEPROM_failure_2 "The configuration EEPROM failed to load or save the module configuration.";
CM_ SG_ 2181529603 Phase_U_2 "Phase current is the MOSFET loop current, in the branch U of the converter.";
CM_ SG_ 2181529603 Phase_V_2 "Phase current is the MOSFET loop current, in the branch V of the converter.";
CM_ SG_ 2181529603 Phase_W_2 "Phase current is the MOSFET loop current, in the branch W of the converter.";
CM_ SG_ 2181529616 Bus_current_2 "DC Bus current is possitive when current goes from input to output";
CM_ SG_ 2181529614 Phase_U_2 "Phase current is the MOSFET loop current, in the branch U of the converter.";
CM_ SG_ 2181529614 Phase_V_2 "Phase current is the MOSFET loop current, in the branch V of the converter.";
CM_ SG_ 2181529614 Phase_W_2 "Phase current is the MOSFET loop current, in the branch W of the converter.";
CM_ SG_ 2181529614 Stack_position_2 "Sender Stack position";
CM_ SG_ 2181529614 Group_ID_2 "Sender Group ID";
CM_ SG_ 2181529611 Phase_U_2 "RMS Phase current is the MOSFET loop current, in the branch U of the converter.";
CM_ SG_ 2181529611 Phase_V_2 "RMS Phase current is the MOSFET loop current, in the branch V of the converter.";
CM_ SG_ 2181529611 Phase_W_2 "RMS Phase current is the MOSFET loop current, in the branch W of the converter.";
CM_ SG_ 2181529612 Frequency_2 "Frequency of Three-Phase system";
CM_ SG_ 2181529612 Phase_2 "Phase of Three-Phase system";
CM_ SG_ 2181529605 Temp_Bridge_2 "Temperature of the MOSFET block";
CM_ SG_ 2181529605 Temp_Inductors_2 "Temperature of the inductors";
CM_ SG_ 2181529608 Phase_U_2 "The actual PWM duty cycle setpoint";
CM_ SG_ 2181529608 Phase_V_2 "The actual PWM duty cycle setpoint";
CM_ SG_ 2181529608 Phase_W_2 "The actual PWM duty cycle setpoint";
CM_ SG_ 2181529609 Current_setpoint_2 "The actual current setpoint";
CM_ SG_ 2181529609 Voltage_setpoint_2 "The actual voltage setpoint";
CM_ SG_ 2181529609 Frequency_setpoint_2 "The actual frequency setpoint";
CM_ SG_ 2181496928 Keep_Alive_Enable_2 "If set to 1, module will expect to receive this message every second repeatedly, or it will stop operation";
CM_ SG_ 2181496896 Converter_ON_2 "Enable the converter.";
CM_ SG_ 2181496896 PWM_ON_2 "Enable the PWM control mode.";
CM_ SG_ 2181496896 DC_Current_feedback_ON_2 "Enable the DC current loop";
CM_ SG_ 2181496896 AC_Current_feedback_ON_2 "Enable the AC current loop";
CM_ SG_ 2181496896 Buck_ON_2 "Enable the buck control mode.";
CM_ SG_ 2181496896 Boost_ON_2 "Enable the boost control mode.";
CM_ SG_ 2181496896 Rectifier_3ph_ON_2 "Enable the three-phase rectifier control mode.";
CM_ SG_ 2181496896 Inverter_1ph_ON_2 "Enable the single-phase inverter control mode.";
CM_ SG_ 2181496896 Rectifier_1ph_ON_2 "Enable the single-phase rectifier control mode.";
CM_ SG_ 2181496896 Boost_Neutral_ON_2 "Enable the boost control mode with neutral generation.";
CM_ SG_ 2181496896 Inverter_3ph_ON_2 "Enable the three-phase inverter control mode.";
CM_ SG_ 2181496896 Inverter_1ph_Sync_ON_2 "Single-phase inverter control mode with phase synchronization.";
CM_ SG_ 2181496896 Neutral_ON_2 "Open-loop neutral generation.";
CM_ SG_ 2181496896 Rectifier_1ph_Buck_ON_2 "Single-phase rectifier with buck on one leg.";
CM_ SG_ 2181496896 Inverter_1ph_Boost_ON_2 "Single-phase inverter with boost on one leg.";
CM_ SG_ 2181496896 Rectifier_Distributed_ON_2 "Single-phase (floating) distributed rectifier";
CM_ SG_ 2181496896 MPPT_buck_ON_2 "MPPT buck";
CM_ SG_ 2181496896 MPPT_boost_ON_2 "MPPT boost";
CM_ SG_ 2181496896 Buck_2p_float_ON_2 "Boost on L1 and L2. Floating L3 (high-impedance)";
CM_ SG_ 2181496896 Inverter_1ph_Distributed_ON_2 "Single-phase inverter mode distributed";
CM_ SG_ 2181496912 Clear_Interlock_2 "Clears the converter interlock";
CM_ SG_ 2181496912 Reset_Processor_2 "Reset the converter DSP";
CM_ SG_ 2181496912 Trip_Interlock_2 "Trip the inetrnal Interlock";
CM_ SG_ 2181496897 Reactive_current_setpoint_2 "This defines reactive current setpoint for 3-phase rectifier mode";
CM_ SG_ 2181496898 Phase_U_2 "The actual PWM duty cycle setpoint";
CM_ SG_ 2181496898 Phase_V_2 "The actual PWM duty cycle setpoint";
CM_ SG_ 2181496898 Phase_W_2 "The actual PWM duty cycle setpoint";
CM_ SG_ 2181496899 Current_setpoint_2 "Sets the output current setpoint. Active only when the current loop is enabled";
CM_ SG_ 2181496900 Voltage_setpoint_2 "Sets the output voltage setpoint. Active only when the voltage loop is enabled";
CM_ SG_ 2181496904 Frequency_setpoint_2 "Sets the frequency for single-phase and three-phase generator modes.";
CM_ SG_ 2181496905 Phase_setpoint_2 "Sets the phase for inverter control modes.";
CM_ SG_ 2181496901 Stack_position_2 "The converter position within the stack";
CM_ SG_ 2181496901 Stack_size_2 "How many PFC converters are in stack in total";
CM_ SG_ 2181496901 SN_number_2 "Unique module serial number";
CM_ SG_ 2181496880 Phase_voltage_min_2 "Minimum tolerated phase voltage";
CM_ SG_ 2181496880 Phase_voltage_max_2 "Maximum allowable phase voltage";
CM_ SG_ 2181496880 DC_voltage_min_2 "Minimum allowable dc voltage";
CM_ SG_ 2181496880 DC_voltage_max_2 "Maximum allowable dc voltage";
CM_ SG_ 2181496881 Phase_current_min_2 "Minimum allowable output current";
CM_ SG_ 2181496881 Phase_current_max_2 "Maximum allowable output current";
CM_ SG_ 2181496908 Group_ID_2 "Desired group ID for the device";
CM_ SG_ 2181529615 Group_ID_2 "Group ID of the device";
CM_ SG_ 2181496929 Factory_mode_2 "Customers MUST NOT USE this bit. If set to 1, module will enter in factory mode. ";
CM_ SG_ 2181496929 Silent_CAN_mode_2 "Customers MUST NOT USE this bit. If set to 1, module will enter in factory mode. ";
CM_ SG_ 2181496906 start_2 "Start automatic calibration. Multiplexer index must be 0!";
CM_ SG_ 2181496907 point_2 "Calibration point index.";
CM_ SG_ 2181496902 CRC_2 "Checksum of bytes 0 to 3, CRC-CCITT, corresponding to qChecksum (www.qt.io)";
CM_ SG_ 2181496903 CRC_2 "Checksum of bytes 0 to 3, CRC-CCITT, corresponding to qChecksum (www.qt.io)";
CM_ SG_ 2181529686 Current_U_High_2 "This flag is set if a hight current on U tripped the internal interlock";
CM_ SG_ 2181529686 Current_U_Low_2 "This flag is set if a low current on U tripped the internal interlock";
CM_ SG_ 2181529686 Current_V_High_2 "This flag is set if a hight current on V tripped the internal interlock";
CM_ SG_ 2181529686 Current_V_Low_2 "This flag is set if a low current on V tripped the internal interlock";
CM_ SG_ 2181529686 Current_W_High_2 "This flag is set if a hight current on W tripped the internal interlock";
CM_ SG_ 2181529686 Current_W_Low_2 "This flag is set if a low current on W tripped the internal interlock";
CM_ SG_ 2181529686 Voltage_DC_2 "This flag is set if a voltage on DC tripped the internal interlock";
CM_ SG_ 2181529686 Reboot_2 "This flag is set if a reboot tripped the internal interlock";
CM_ SG_ 2181529686 Unknown_2 "This flag the reason for the internal interlock is unknown";

BA_DEF_ BO_ "SystemMessageLongSymbol" STRING;

BA_ "SystemMessageLongSymbol" BO_ 2181496897 "AFE_Reactive_Current_Setpoint_Control_2";

VAL_ 2181529600 Device_type_2 7 "AFE";
VAL_ 2181529606 Protection_trip_internal_2 1 "fault";
VAL_ 2181529606 Protection_trip_external_2 1 "fault";
VAL_ 2181529606 Phase_U_overcurrent_2 1 "fault";
VAL_ 2181529606 Phase_U_overvoltage_2 1 "fault";
VAL_ 2181529606 Phase_U_undervoltage_2 1 "fault";
VAL_ 2181529606 Phase_V_overvoltage_2 1 "fault";
VAL_ 2181529606 Phase_V_undervoltage_2 1 "fault";
VAL_ 2181529606 Phase_V_overcurrent_2 1 "fault";
VAL_ 2181529606 Phase_W_overvoltage_2 1 "fault";
VAL_ 2181529606 Phase_W_undervoltage_2 1 "fault";
VAL_ 2181529606 Phase_W_overcurrent_2 1 "fault";
VAL_ 2181529606 DC_undervoltage_2 1 "fault";
VAL_ 2181529606 DC_overvoltage_2 1 "fault";
VAL_ 2181529606 MOSFET_overtemperature_2 1 "fault";
VAL_ 2181529606 Inductor_overtemperature_2 1 "fault";
VAL_ 2181529606 Keep_Alive_not_served_2 1 "fault";
VAL_ 2181529606 PLL_not_locked_2 1 "fault";
VAL_ 2181529606 NFO_2 1 "fault";
VAL_ 2181529606 Measurement_system_failure_2 1 "fault";
VAL_ 2181529606 EEPROM_failure_2 1 "fault";
VAL_ 2181529606 System_2 1 "fault";
VAL_ 2181529686 Current_U_High_2 1 "fault";
VAL_ 2181529686 Current_U_Low_2 1 "fault";
VAL_ 2181529686 Current_V_High_2 1 "fault";
VAL_ 2181529686 Current_V_Low_2 1 "fault";
VAL_ 2181529686 Current_W_High_2 1 "fault";
VAL_ 2181529686 Current_W_Low_2 1 "fault";
VAL_ 2181529686 Voltage_DC_2 1 "fault";
VAL_ 2181529686 Reboot_2 1 "fault";
VAL_ 2181529686 Unknown_2 1 "fault";
SIG_VALTYPE_ 2181529681 Current_U_2 : 1;
SIG_VALTYPE_ 2181529681 Current_V_2 : 1;
SIG_VALTYPE_ 2181529681 Current_W_2 : 1;
SIG_VALTYPE_ 2181529681 Voltage_U_2 : 1;
SIG_VALTYPE_ 2181529681 Voltage_V_2 : 1;
SIG_VALTYPE_ 2181529681 Voltage_W_2 : 1;
SIG_VALTYPE_ 2181529681 Voltage_DC_2 : 1;
SIG_VALTYPE_ 2181529682 Current_U_2 : 1;
SIG_VALTYPE_ 2181529682 Current_V_2 : 1;
SIG_VALTYPE_ 2181529682 Current_W_2 : 1;
SIG_VALTYPE_ 2181529682 Voltage_U_2 : 1;
SIG_VALTYPE_ 2181529682 Voltage_V_2 : 1;
SIG_VALTYPE_ 2181529682 Voltage_W_2 : 1;
SIG_VALTYPE_ 2181529682 Voltage_DC_2 : 1;
